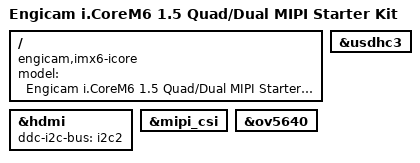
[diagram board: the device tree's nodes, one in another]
/dts-v1/;
#include "imx6q.dtsi"
#include "imx6qdl-icore-1.5.dtsi"
/ {
	model = "Engicam i.CoreM6 1.5 Quad/Dual MIPI Starter Kit";
	compatible = "engicam,imx6-icore", "fsl,imx6q";
};
&hdmi {
	ddc-i2c-bus = <&i2c2>;
	status = "okay";
};
&mipi_csi {
	status = "okay";
};
&ov5640 {
	status = "okay";
};
&usdhc3 {
	status = "okay";
};
